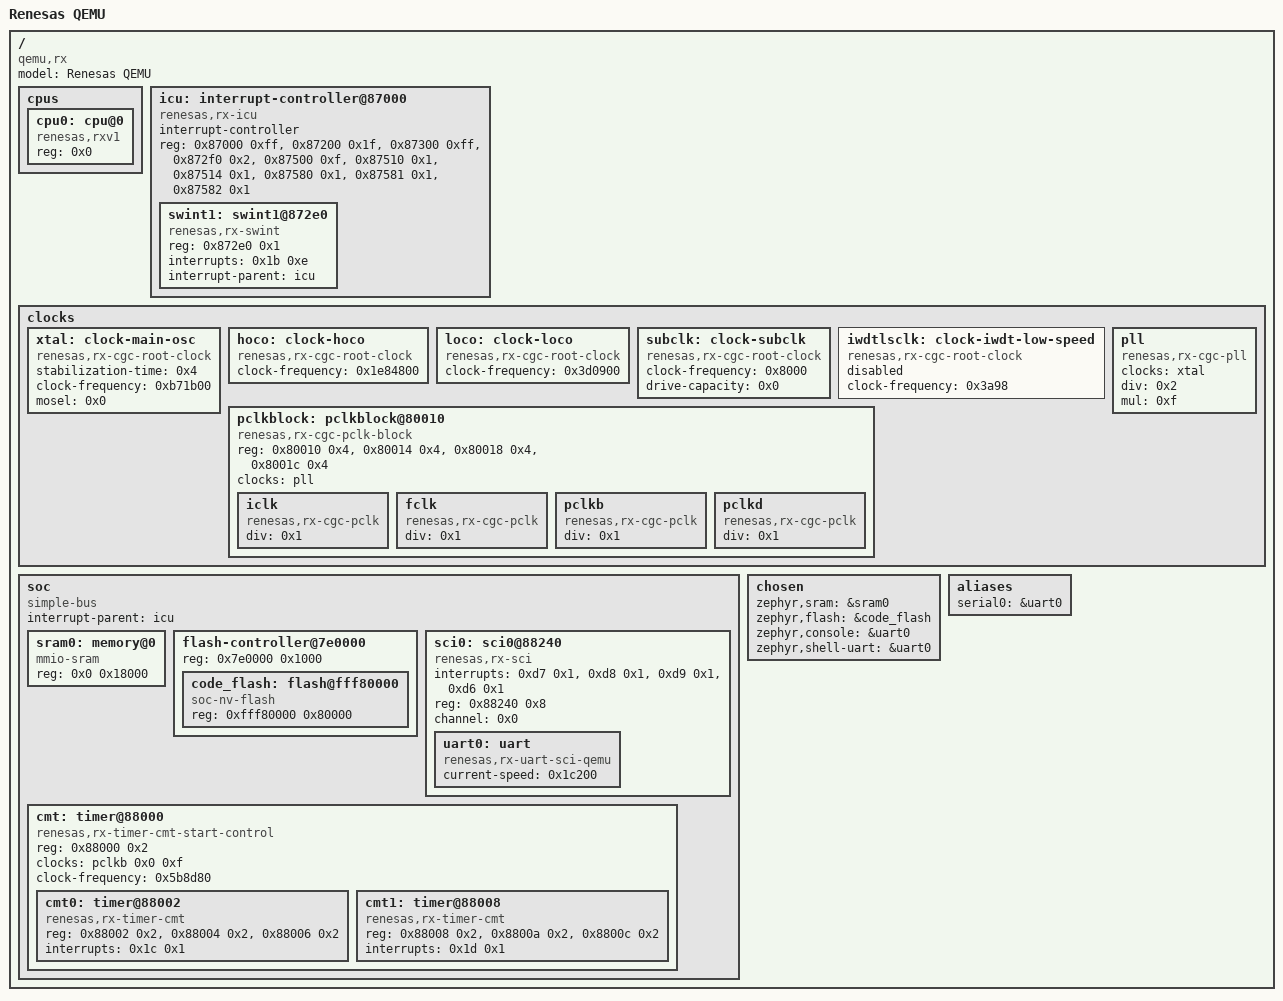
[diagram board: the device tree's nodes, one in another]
/dts-v1/;

/* node '/' defined in zephyr/dts/rx/renesas/rx-qemu.dtsi:16 */
/ {
	#address-cells = < 0x1 >; /* in zephyr/dts/rx/renesas/rx-qemu.dtsi:17 */
	#size-cells = < 0x1 >;    /* in zephyr/dts/rx/renesas/rx-qemu.dtsi:18 */
	model = "Renesas QEMU";   /* in zephyr/boards/qemu/rx/qemu_rx.dts:13 */
	compatible = "qemu,rx";   /* in zephyr/boards/qemu/rx/qemu_rx.dts:14 */

	/* node '/cpus' defined in zephyr/dts/rx/renesas/rx-qemu.dtsi:20 */
	cpus {
		#address-cells = < 0x1 >; /* in zephyr/dts/rx/renesas/rx-qemu.dtsi:21 */
		#size-cells = < 0x0 >;    /* in zephyr/dts/rx/renesas/rx-qemu.dtsi:22 */

		/* node '/cpus/cpu@0' defined in zephyr/dts/rx/renesas/rx-qemu.dtsi:24 */
		cpu0: cpu@0 {
			compatible = "renesas,rxv1"; /* in zephyr/dts/rx/renesas/rx-qemu.dtsi:25 */
			device_type = "cpu";         /* in zephyr/dts/rx/renesas/rx-qemu.dtsi:26 */
			reg = < 0x0 >;               /* in zephyr/dts/rx/renesas/rx-qemu.dtsi:27 */
			status = "okay";             /* in zephyr/dts/rx/renesas/rx-qemu.dtsi:28 */
		};
	};

	/* node '/interrupt-controller@87000' defined in zephyr/dts/rx/renesas/rx-qemu.dtsi:32 */
	icu: interrupt-controller@87000 {
		#interrupt-cells = < 0x2 >;    /* in zephyr/dts/rx/renesas/rx-qemu.dtsi:33 */
		#address-cells = < 0x1 >;      /* in zephyr/dts/rx/renesas/rx-qemu.dtsi:34 */
		#size-cells = < 0x1 >;         /* in zephyr/dts/rx/renesas/rx-qemu.dtsi:35 */
		compatible = "renesas,rx-icu"; /* in zephyr/dts/rx/renesas/rx-qemu.dtsi:36 */
		interrupt-controller;          /* in zephyr/dts/rx/renesas/rx-qemu.dtsi:37 */
		reg = < 0x87000 0xff >,
		      < 0x87200 0x1f >,
		      < 0x87300 0xff >,
		      < 0x872f0 0x2 >,
		      < 0x87500 0xf >,
		      < 0x87510 0x1 >,
		      < 0x87514 0x1 >,
		      < 0x87580 0x1 >,
		      < 0x87581 0x1 >,
		      < 0x87582 0x1 >;         /* in zephyr/dts/rx/renesas/rx-qemu.dtsi:38 */
		reg-names = "IR",
		            "IER",
		            "IPR",
		            "FIR",
		            "IRQCR",
		            "IRQFLTE",
		            "IRQFLTC0",
		            "NMISR",
		            "NMIER",
		            "NMICLR";          /* in zephyr/dts/rx/renesas/rx-qemu.dtsi:48 */
		phandle = < 0x1 >;             /* in zephyr/dts/rx/renesas/rx-qemu.dtsi:55 */

		/* node '/interrupt-controller@87000/swint1@872e0' defined in zephyr/dts/rx/renesas/rx-qemu.dtsi:51 */
		swint1: swint1@872e0 {
			compatible = "renesas,rx-swint"; /* in zephyr/dts/rx/renesas/rx-qemu.dtsi:52 */
			reg = < 0x872e0 0x1 >;           /* in zephyr/dts/rx/renesas/rx-qemu.dtsi:53 */
			interrupts = < 0x1b 0xe >;       /* in zephyr/dts/rx/renesas/rx-qemu.dtsi:54 */
			interrupt-parent = < &icu >;     /* in zephyr/dts/rx/renesas/rx-qemu.dtsi:55 */
			status = "okay";                 /* in zephyr/dts/rx/renesas/rx-qemu.dtsi:56 */
		};
	};

	/* node '/clocks' defined in zephyr/dts/rx/renesas/rx-qemu.dtsi:60 */
	clocks: clocks {
		#address-cells = < 0x1 >; /* in zephyr/dts/rx/renesas/rx-qemu.dtsi:61 */
		#size-cells = < 0x1 >;    /* in zephyr/dts/rx/renesas/rx-qemu.dtsi:62 */

		/* node '/clocks/clock-main-osc' defined in zephyr/dts/rx/renesas/rx-qemu.dtsi:64 */
		xtal: clock-main-osc {
			compatible = "renesas,rx-cgc-root-clock"; /* in zephyr/dts/rx/renesas/rx-qemu.dtsi:65 */
			stabilization-time = < 0x4 >;             /* in zephyr/dts/rx/renesas/rx-qemu.dtsi:68 */
			clock-frequency = < 0xb71b00 >;           /* in zephyr/boards/qemu/rx/qemu_rx.dts:38 */
			mosel = < 0x0 >;                          /* in zephyr/boards/qemu/rx/qemu_rx.dts:39 */
			#clock-cells = < 0x0 >;                   /* in zephyr/boards/qemu/rx/qemu_rx.dts:40 */
			status = "okay";                          /* in zephyr/boards/qemu/rx/qemu_rx.dts:41 */
			phandle = < 0x2 >;                        /* in zephyr/dts/rx/renesas/rx-qemu.dtsi:106 */
		};

		/* node '/clocks/clock-hoco' defined in zephyr/dts/rx/renesas/rx-qemu.dtsi:73 */
		hoco: clock-hoco {
			compatible = "renesas,rx-cgc-root-clock"; /* in zephyr/dts/rx/renesas/rx-qemu.dtsi:74 */
			clock-frequency = < 0x1e84800 >;          /* in zephyr/dts/rx/renesas/rx-qemu.dtsi:75 */
			#clock-cells = < 0x0 >;                   /* in zephyr/dts/rx/renesas/rx-qemu.dtsi:76 */
			status = "okay";                          /* in zephyr/dts/rx/renesas/rx-qemu.dtsi:77 */
		};

		/* node '/clocks/clock-loco' defined in zephyr/dts/rx/renesas/rx-qemu.dtsi:80 */
		loco: clock-loco {
			compatible = "renesas,rx-cgc-root-clock"; /* in zephyr/dts/rx/renesas/rx-qemu.dtsi:81 */
			clock-frequency = < 0x3d0900 >;           /* in zephyr/dts/rx/renesas/rx-qemu.dtsi:82 */
			#clock-cells = < 0x0 >;                   /* in zephyr/dts/rx/renesas/rx-qemu.dtsi:83 */
			status = "okay";                          /* in zephyr/dts/rx/renesas/rx-qemu.dtsi:84 */
		};

		/* node '/clocks/clock-subclk' defined in zephyr/dts/rx/renesas/rx-qemu.dtsi:87 */
		subclk: clock-subclk {
			compatible = "renesas,rx-cgc-root-clock"; /* in zephyr/dts/rx/renesas/rx-qemu.dtsi:88 */
			clock-frequency = < 0x8000 >;             /* in zephyr/dts/rx/renesas/rx-qemu.dtsi:89 */
			drive-capacity = < 0x0 >;                 /* in zephyr/dts/rx/renesas/rx-qemu.dtsi:90 */
			#clock-cells = < 0x0 >;                   /* in zephyr/dts/rx/renesas/rx-qemu.dtsi:91 */
			status = "okay";                          /* in zephyr/boards/qemu/rx/qemu_rx.dts:45 */
		};

		/* node '/clocks/clock-iwdt-low-speed' defined in zephyr/dts/rx/renesas/rx-qemu.dtsi:95 */
		iwdtlsclk: clock-iwdt-low-speed {
			compatible = "renesas,rx-cgc-root-clock"; /* in zephyr/dts/rx/renesas/rx-qemu.dtsi:96 */
			clock-frequency = < 0x3a98 >;             /* in zephyr/dts/rx/renesas/rx-qemu.dtsi:97 */
			#clock-cells = < 0x0 >;                   /* in zephyr/dts/rx/renesas/rx-qemu.dtsi:98 */
			status = "disabled";                      /* in zephyr/dts/rx/renesas/rx-qemu.dtsi:99 */
		};

		/* node '/clocks/pll' defined in zephyr/dts/rx/renesas/rx-qemu.dtsi:102 */
		pll: pll {
			compatible = "renesas,rx-cgc-pll"; /* in zephyr/dts/rx/renesas/rx-qemu.dtsi:103 */
			#clock-cells = < 0x0 >;            /* in zephyr/dts/rx/renesas/rx-qemu.dtsi:104 */
			clocks = < &xtal >;                /* in zephyr/dts/rx/renesas/rx-qemu.dtsi:106 */
			div = < 0x2 >;                     /* in zephyr/boards/qemu/rx/qemu_rx.dts:49 */
			mul = < 0xf >;                     /* in zephyr/boards/qemu/rx/qemu_rx.dts:50 */
			status = "okay";                   /* in zephyr/boards/qemu/rx/qemu_rx.dts:51 */
			phandle = < 0x3 >;                 /* in zephyr/dts/rx/renesas/rx-qemu.dtsi:117 */
		};

		/* node '/clocks/pclkblock@80010' defined in zephyr/dts/rx/renesas/rx-qemu.dtsi:111 */
		pclkblock: pclkblock@80010 {
			compatible = "renesas,rx-cgc-pclk-block"; /* in zephyr/dts/rx/renesas/rx-qemu.dtsi:112 */
			reg = < 0x80010 0x4 >,
			      < 0x80014 0x4 >,
			      < 0x80018 0x4 >,
			      < 0x8001c 0x4 >;                    /* in zephyr/dts/rx/renesas/rx-qemu.dtsi:113 */
			reg-names = "MSTPA",
			            "MSTPB",
			            "MSTPC",
			            "MSTPD";                      /* in zephyr/dts/rx/renesas/rx-qemu.dtsi:115 */
			#clock-cells = < 0x0 >;                   /* in zephyr/dts/rx/renesas/rx-qemu.dtsi:116 */
			clocks = < &pll >;                        /* in zephyr/dts/rx/renesas/rx-qemu.dtsi:117 */
			status = "okay";                          /* in zephyr/dts/rx/renesas/rx-qemu.dtsi:118 */

			/* node '/clocks/pclkblock@80010/iclk' defined in zephyr/dts/rx/renesas/rx-qemu.dtsi:120 */
			iclk: iclk {
				compatible = "renesas,rx-cgc-pclk"; /* in zephyr/dts/rx/renesas/rx-qemu.dtsi:121 */
				div = < 0x1 >;                      /* in zephyr/dts/rx/renesas/rx-qemu.dtsi:122 */
				#clock-cells = < 0x2 >;             /* in zephyr/dts/rx/renesas/rx-qemu.dtsi:123 */
				status = "okay";                    /* in zephyr/dts/rx/renesas/rx-qemu.dtsi:124 */
			};

			/* node '/clocks/pclkblock@80010/fclk' defined in zephyr/dts/rx/renesas/rx-qemu.dtsi:127 */
			fclk: fclk {
				compatible = "renesas,rx-cgc-pclk"; /* in zephyr/dts/rx/renesas/rx-qemu.dtsi:128 */
				div = < 0x1 >;                      /* in zephyr/dts/rx/renesas/rx-qemu.dtsi:129 */
				#clock-cells = < 0x2 >;             /* in zephyr/dts/rx/renesas/rx-qemu.dtsi:130 */
				status = "okay";                    /* in zephyr/dts/rx/renesas/rx-qemu.dtsi:131 */
			};

			/* node '/clocks/pclkblock@80010/pclkb' defined in zephyr/dts/rx/renesas/rx-qemu.dtsi:134 */
			pclkb: pclkb {
				compatible = "renesas,rx-cgc-pclk"; /* in zephyr/dts/rx/renesas/rx-qemu.dtsi:135 */
				div = < 0x1 >;                      /* in zephyr/dts/rx/renesas/rx-qemu.dtsi:136 */
				#clock-cells = < 0x2 >;             /* in zephyr/dts/rx/renesas/rx-qemu.dtsi:137 */
				status = "okay";                    /* in zephyr/dts/rx/renesas/rx-qemu.dtsi:138 */
				phandle = < 0x4 >;                  /* in zephyr/dts/rx/renesas/rx-qemu.dtsi:192 */
			};

			/* node '/clocks/pclkblock@80010/pclkd' defined in zephyr/dts/rx/renesas/rx-qemu.dtsi:141 */
			pclkd: pclkd {
				compatible = "renesas,rx-cgc-pclk"; /* in zephyr/dts/rx/renesas/rx-qemu.dtsi:142 */
				div = < 0x1 >;                      /* in zephyr/dts/rx/renesas/rx-qemu.dtsi:143 */
				#clock-cells = < 0x2 >;             /* in zephyr/dts/rx/renesas/rx-qemu.dtsi:144 */
				status = "okay";                    /* in zephyr/dts/rx/renesas/rx-qemu.dtsi:145 */
			};
		};
	};

	/* node '/soc' defined in zephyr/dts/rx/renesas/rx-qemu.dtsi:150 */
	soc {
		#address-cells = < 0x1 >;    /* in zephyr/dts/rx/renesas/rx-qemu.dtsi:151 */
		#size-cells = < 0x1 >;       /* in zephyr/dts/rx/renesas/rx-qemu.dtsi:152 */
		compatible = "simple-bus";   /* in zephyr/dts/rx/renesas/rx-qemu.dtsi:153 */
		interrupt-parent = < &icu >; /* in zephyr/dts/rx/renesas/rx-qemu.dtsi:154 */

		/* node '/soc/memory@0' defined in zephyr/dts/rx/renesas/rx-qemu.dtsi:156 */
		sram0: memory@0 {
			device_type = "memory";   /* in zephyr/dts/rx/renesas/rx-qemu.dtsi:157 */
			compatible = "mmio-sram"; /* in zephyr/dts/rx/renesas/rx-qemu.dtsi:158 */
			reg = < 0x0 0x18000 >;    /* in zephyr/dts/rx/renesas/rx-qemu.dtsi:159 */
		};

		/* node '/soc/flash-controller@7e0000' defined in zephyr/dts/rx/renesas/rx-qemu.dtsi:162 */
		flash-controller@7e0000 {
			reg = < 0x7e0000 0x1000 >; /* in zephyr/dts/rx/renesas/rx-qemu.dtsi:163 */
			#address-cells = < 0x1 >;  /* in zephyr/dts/rx/renesas/rx-qemu.dtsi:164 */
			#size-cells = < 0x1 >;     /* in zephyr/dts/rx/renesas/rx-qemu.dtsi:165 */

			/* node '/soc/flash-controller@7e0000/flash@fff80000' defined in zephyr/dts/rx/renesas/rx-qemu.dtsi:167 */
			code_flash: flash@fff80000 {
				compatible = "soc-nv-flash";  /* in zephyr/dts/rx/renesas/rx-qemu.dtsi:168 */
				reg = < 0xfff80000 0x80000 >; /* in zephyr/dts/rx/renesas/rx-qemu.dtsi:169 */
			};
		};

		/* node '/soc/sci0@88240' defined in zephyr/dts/rx/renesas/rx-qemu.dtsi:173 */
		sci0: sci0@88240 {
			compatible = "renesas,rx-sci"; /* in zephyr/dts/rx/renesas/rx-qemu.dtsi:174 */
			interrupts = < 0xd7 0x1 >,
			             < 0xd8 0x1 >,
			             < 0xd9 0x1 >,
			             < 0xd6 0x1 >;     /* in zephyr/dts/rx/renesas/rx-qemu.dtsi:175 */
			interrupt-names = "rxi",
			                  "txi",
			                  "tei",
			                  "eri";       /* in zephyr/dts/rx/renesas/rx-qemu.dtsi:176 */
			reg = < 0x88240 0x8 >;         /* in zephyr/dts/rx/renesas/rx-qemu.dtsi:177 */
			channel = < 0x0 >;             /* in zephyr/dts/rx/renesas/rx-qemu.dtsi:179 */
			status = "okay";               /* in zephyr/boards/qemu/rx/qemu_rx.dts:29 */

			/* node '/soc/sci0@88240/uart' defined in zephyr/dts/rx/renesas/rx-qemu.dtsi:181 */
			uart0: uart {
				compatible = "renesas,rx-uart-sci-qemu"; /* in zephyr/dts/rx/renesas/rx-qemu.dtsi:182 */
				current-speed = < 0x1c200 >;             /* in zephyr/boards/qemu/rx/qemu_rx.dts:32 */
				status = "okay";                         /* in zephyr/boards/qemu/rx/qemu_rx.dts:33 */
			};
		};

		/* node '/soc/timer@88000' defined in zephyr/dts/rx/renesas/rx-qemu.dtsi:187 */
		cmt: timer@88000 {
			compatible = "renesas,rx-timer-cmt-start-control"; /* in zephyr/dts/rx/renesas/rx-qemu.dtsi:188 */
			#address-cells = < 0x1 >;                          /* in zephyr/dts/rx/renesas/rx-qemu.dtsi:189 */
			#size-cells = < 0x1 >;                             /* in zephyr/dts/rx/renesas/rx-qemu.dtsi:190 */
			reg = < 0x88000 0x2 >;                             /* in zephyr/dts/rx/renesas/rx-qemu.dtsi:191 */
			clocks = < &pclkb 0x0 0xf >;                       /* in zephyr/dts/rx/renesas/rx-qemu.dtsi:192 */
			reg-names = "CMSTR0";                              /* in zephyr/dts/rx/renesas/rx-qemu.dtsi:193 */
			clock-frequency = < 0x5b8d80 >;                    /* in zephyr/boards/qemu/rx/qemu_rx.dts:55 */
			status = "okay";                                   /* in zephyr/boards/qemu/rx/qemu_rx.dts:56 */

			/* node '/soc/timer@88000/timer@88002' defined in zephyr/dts/rx/renesas/rx-qemu.dtsi:196 */
			cmt0: timer@88002 {
				compatible = "renesas,rx-timer-cmt"; /* in zephyr/dts/rx/renesas/rx-qemu.dtsi:197 */
				#address-cells = < 0x1 >;            /* in zephyr/dts/rx/renesas/rx-qemu.dtsi:198 */
				#size-cells = < 0x1 >;               /* in zephyr/dts/rx/renesas/rx-qemu.dtsi:199 */
				reg = < 0x88002 0x2 >,
				      < 0x88004 0x2 >,
				      < 0x88006 0x2 >;               /* in zephyr/dts/rx/renesas/rx-qemu.dtsi:200 */
				reg-names = "CMCR",
				            "CMCNT",
				            "CMCOR";                 /* in zephyr/dts/rx/renesas/rx-qemu.dtsi:203 */
				interrupts = < 0x1c 0x1 >;           /* in zephyr/dts/rx/renesas/rx-qemu.dtsi:204 */
				interrupt-names = "cmi";             /* in zephyr/dts/rx/renesas/rx-qemu.dtsi:205 */
				status = "okay";                     /* in zephyr/dts/rx/renesas/rx-qemu.dtsi:206 */
			};

			/* node '/soc/timer@88000/timer@88008' defined in zephyr/dts/rx/renesas/rx-qemu.dtsi:209 */
			cmt1: timer@88008 {
				compatible = "renesas,rx-timer-cmt"; /* in zephyr/dts/rx/renesas/rx-qemu.dtsi:210 */
				reg = < 0x88008 0x2 >,
				      < 0x8800a 0x2 >,
				      < 0x8800c 0x2 >;               /* in zephyr/dts/rx/renesas/rx-qemu.dtsi:211 */
				reg-names = "CMCR",
				            "CMCNT",
				            "CMCOR";                 /* in zephyr/dts/rx/renesas/rx-qemu.dtsi:214 */
				interrupts = < 0x1d 0x1 >;           /* in zephyr/dts/rx/renesas/rx-qemu.dtsi:215 */
				interrupt-names = "cmi";             /* in zephyr/dts/rx/renesas/rx-qemu.dtsi:216 */
				status = "okay";                     /* in zephyr/dts/rx/renesas/rx-qemu.dtsi:217 */
			};
		};
	};

	/* node '/chosen' defined in zephyr/boards/qemu/rx/qemu_rx.dts:16 */
	chosen {
		zephyr,sram = &sram0;       /* in zephyr/boards/qemu/rx/qemu_rx.dts:17 */
		zephyr,flash = &code_flash; /* in zephyr/boards/qemu/rx/qemu_rx.dts:18 */
		zephyr,console = &uart0;    /* in zephyr/boards/qemu/rx/qemu_rx.dts:19 */
		zephyr,shell-uart = &uart0; /* in zephyr/boards/qemu/rx/qemu_rx.dts:20 */
	};

	/* node '/aliases' defined in zephyr/boards/qemu/rx/qemu_rx.dts:23 */
	aliases {
		serial0 = &uart0; /* in zephyr/boards/qemu/rx/qemu_rx.dts:24 */
	};
};
